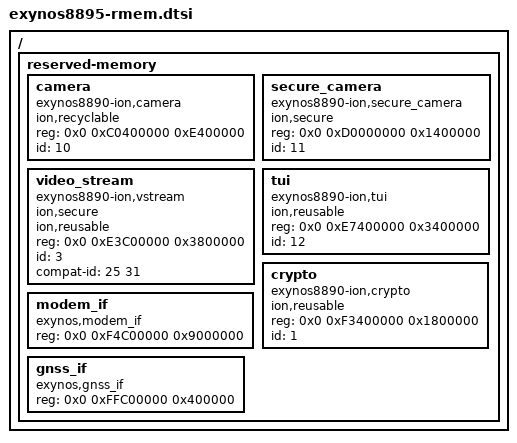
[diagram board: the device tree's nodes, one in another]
/*
 * SAMSUNG EXYNOS device tree source for reserved-memory
 *
 * Copyright (c) 2015 Samsung Electronics Co., Ltd.
 *		http://www.samsung.com
 *
 * This program is free software; you can redistribute it and/or modify
 * it under the terms of the GNU General Public License version 2 as
 * published by the Free Software Foundation.
*/

/memreserve/ 0xE0000000 0x1900000;

/ {
	reserved-memory {
		#address-cells = <2>;
		#size-cells = <1>;
		ranges;


		camera {
			compatible = "exynos8890-ion,camera";
			ion,recyclable;
			reg = <0x0 0xC0400000 0xE400000>;
			id = <10>;
		};

		secure_camera {
			compatible = "exynos8890-ion,secure_camera";
			ion,secure;
			reg = <0x0 0xD0000000 0x1400000>;
			id = <11>;
		};


		video_stream {
			compatible = "exynos8890-ion,vstream";
			ion,secure;
			ion,reusable;
			reg = <0x0 0xE3C00000 0x3800000>;
			id = <3>;
			compat-id = <25 31>;
		};

		tui {
			/* ALIGN(ALIGN(1440*2990*4, 256KB) * 3, 4MB) */
			compatible = "exynos8890-ion,tui";
			ion,reusable;
			reg = <0x0 0xE7400000 0x3400000>;
			id = <12>;
		};

		crypto {
			compatible = "exynos8890-ion,crypto";
			ion,reusable;
			reg = <0x0 0xF3400000 0x1800000>;
			id = <1>;
		};

		modem_if {
			compatible = "exynos,modem_if";
			reg = <0x0 0xF4C00000 0x9000000>;
		};


		gnss_if {
			compatible = "exynos,gnss_if";
			reg = <0x0 0xFFC00000 0x400000>;
		};
	};
};
